AUTOSAR XML (schema 4-2-2)
package /COM_SWC
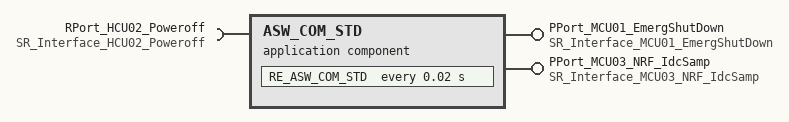
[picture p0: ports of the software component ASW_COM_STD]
  application sw component type ASW_COM_STD
    provide port PPort_MCU01_EmergShutDown: provided-interface=SR_Interface_MCU01_EmergShutDown
    provide port PPort_MCU03_NRF_IdcSamp: provided-interface=SR_Interface_MCU03_NRF_IdcSamp
    require port RPort_HCU02_Poweroff: nonqueued-receiver-com-spec{alive-timeout=0.3, data-element=HCU02_Poweroff}, required-interface=SR_Interface_HCU02_Poweroff
    behavior IB_ASW_COM_STD
      timing event TE_RE_ASW_COM_STD_20ms: start-on-event=RE_ASW_COM_STD, period=0.02
      runnable RE_ASW_COM_STD
        data-receive-point-by-arguments:
          access REC_HCU02_Poweroff_HCU02_Poweroff: accessed-variable=RPort_HCU02_Poweroff.HCU02_Poweroff
        data-send-points:
          access SEND_MCU01_EmergShutDown_MCU01_EmergShutDown: accessed-variable=PPort_MCU01_EmergShutDown.MCU01_EmergShutDown
          access SEND_MCU03_NRF_IdcSamp_MCU03_NRF_IdcSamp: accessed-variable=PPort_MCU03_NRF_IdcSamp.MCU03_NRF_IdcSamp
